# UART8 register map
Registers from a debugger description file.
Registers are 32-bit, access not given, no defined reset value unless marked. A register's access mark holds for its fields unless they carry their own. Addresses are absolute; registers are grouped by the start of their names; lines under a group give offsets from that group; [hi:lo] are bit positions; {n}, {i} and the like mark numbered series; 'fields as' and 'values as' point back to an identical list; <NAME> marks a mode.

## UART8
0x50004000 UART8/DLL
  [7:0] DLL
0x50004000 UART8/THR
  [7:0] THR
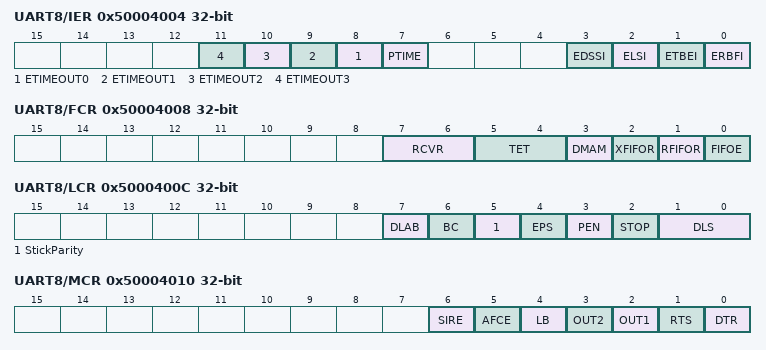
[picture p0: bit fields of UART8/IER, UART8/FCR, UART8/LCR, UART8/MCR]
0x50004004 UART8/IER
  [n+8] ETIMEOUT{n} (n=0..3), [7] PTIME, [3] EDSSI, [2] ELSI, [1] ETBEI, [0] ERBFI
0x50004004 UART8/DLH
  [7:0] DLH
0x50004008 UART8/FCR
  [7:6] RCVR, [5:4] TET, [3] DMAM, [2] XFIFOR, [1] RFIFOR, [0] FIFOE
0x5000400C UART8/LCR
  [7] DLAB, [6] BC, [5] StickParity, [4] EPS, [3] PEN, [2] STOP, [1:0] DLS
0x50004010 UART8/MCR
  [6] SIRE, [5] AFCE, [4] LB, [3] OUT2, [2] OUT1, [1] RTS, [0] DTR
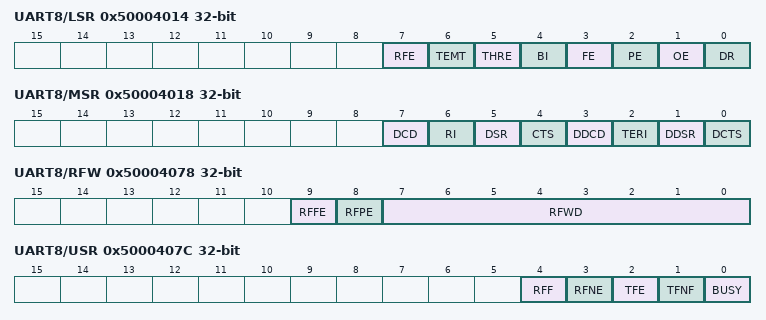
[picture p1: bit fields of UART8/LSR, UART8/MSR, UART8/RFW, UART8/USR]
0x50004014 UART8/LSR ro
  [7] RFE, [6] TEMT, [5] THRE, [4] BI, [3] FE, [2] PE, [1] OE, [0] DR
0x50004018 UART8/MSR ro
  [7] DCD, [6] RI, [5] DSR, [4] CTS, [3] DDCD, [2] TERI, [1] DDSR, [0] DCTS
0x5000401C UART8/SCR
  [7:0] SCR
0x50004030 UART8/STHR
  [7:0] STHR
0x50004070 UART8/FAR
  [0] FAR
0x50004074 UART8/TFR ro
  [7:0] TFR
0x50004078 UART8/RFW
  [9] RFFE, [8] RFPE, [7:0] RFWD
0x5000407C UART8/USR ro
  [4] RFF, [3] RFNE, [2] TFE, [1] TFNF, [0] BUSY
0x50004080 UART8/TFL ro
  [4:0] TFL
0x50004084 UART8/RFL ro
  [4:0] RFL
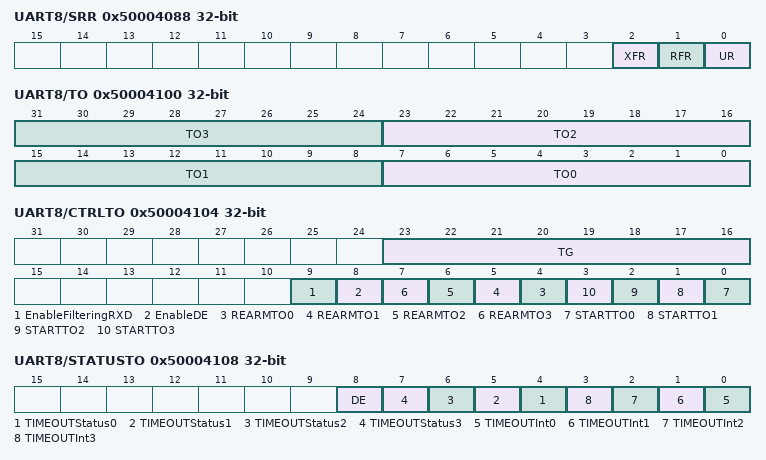
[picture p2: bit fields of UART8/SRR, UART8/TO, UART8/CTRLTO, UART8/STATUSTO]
0x50004088 UART8/SRR
  [2] XFR, [1] RFR, [0] UR
0x5000408C UART8/SRTS
  [0] SRTS
0x50004090 UART8/SBCR
  [0] SBCR
0x50004098 UART8/SFE
  [0] SFE
0x5000409C UART8/SRT
  [1:0] SRCVR
0x500040A0 UART8/STET
  [1:0] STET
0x500040A4 UART8/HTX
  [0] HTX
0x500040A8 UART8/DMASA
  [0] DMASA
0x500040F8 UART8/UCV ro
  [31:0] Version
0x500040FC UART8/CTR ro
  [31:0] ID
0x50004100 UART8/TO
  [8n+7:8n] TO{n} (n=0..3)
0x50004104 UART8/CTRLTO
  [23:16] TG, [9] EnableFilteringRXD, [8] EnableDE, [n+4] REARMTO{n} (n=0..3), [n] STARTTO{n} (n=0..3)
0x50004108 UART8/STATUSTO
  [8] DE, [n+4] TIMEOUTStatus{n} (n=0..3), [n] TIMEOUTInt{n} (n=0..3)
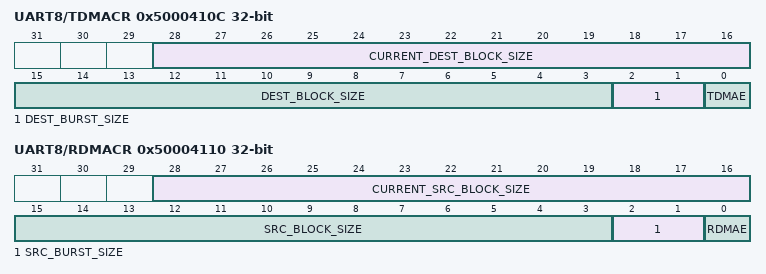
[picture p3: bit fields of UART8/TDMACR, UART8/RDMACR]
0x5000410C UART8/TDMACR
  [28:16] CURRENT_DEST_BLOCK_SIZE, [15:3] DEST_BLOCK_SIZE, [2:1] DEST_BURST_SIZE, [0] TDMAE
0x50004110 UART8/RDMACR
  [28:16] CURRENT_SRC_BLOCK_SIZE, [15:3] SRC_BLOCK_SIZE, [2:1] SRC_BURST_SIZE, [0] RDMAE
